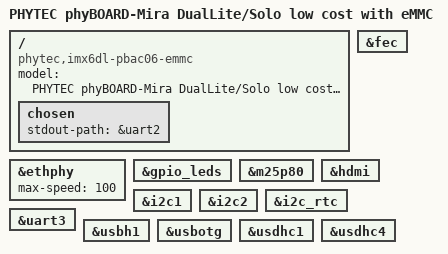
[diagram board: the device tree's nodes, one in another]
// SPDX-License-Identifier: (GPL-2.0+ OR MIT)
/*
 * Copyright (C) 2018 PHYTEC Messtechnik
 * Author: Stefan Christ <s.christ@phytec.de>
 */

/dts-v1/;
#include "imx6dl.dtsi"
#include "imx6qdl-phytec-phycore-som.dtsi"
#include "imx6qdl-phytec-mira.dtsi"
#include "imx6qdl-phytec-mira-peb-eval-01.dtsi"
#include "imx6qdl-phytec-mira-peb-av-02.dtsi"
#include "imx6qdl-phytec-peb-wlbt-01.dtsi"

/ {
	model = "PHYTEC phyBOARD-Mira DualLite/Solo low cost with eMMC";
	compatible = "phytec,imx6dl-pbac06-emmc", "phytec,imx6dl-pbac06",
		     "phytec,imx6qdl-pcm058", "fsl,imx6dl";

	chosen {
		stdout-path = &uart2;
	};
};

&ethphy {
	max-speed = <100>;
};

&fec {
	status = "okay";
};

&gpio_leds {
	status = "okay";
};

&m25p80 {
	status = "okay";
};

&hdmi {
	status = "okay";
};

&i2c1 {
	status = "okay";
};

&i2c2 {
	status = "okay";
};

&i2c_rtc {
	status = "okay";
};

&uart3 {
	status = "okay";
};

&usbh1 {
	status = "okay";
};

&usbotg {
	status = "okay";
};

&usdhc1 {
	status = "okay";
};

&usdhc4 {
	status = "okay";
};
